# MKL28T7_CORE1 register map
Vendor: Freescale Semiconductor, Inc.; Series: Kinetis_L; File version: 1.6
CPU: CM0PLUS r0p0, little endian, no MPU, no FPU, VTOR, 2 interrupt priority bits
Registers are 32-bit, read-write, reset 0x0 unless marked. A register's access mark holds for its fields unless they carry their own. Offsets are from the block's base; [hi:lo] are bit positions; {n}, {i} and the like mark numbered series.

## VREF — Voltage Reference
Base 0x40072000; register names take the prefix VREF_
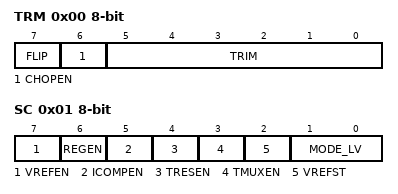
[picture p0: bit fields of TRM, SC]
0x00 TRM 8-bit (reset mask 0xC0) — VREF Trim Register
  [7] FLIP — Reverses the amplifier polarity
  [6] CHOPEN — Chop oscillator enable. When set, the internal chopping operation is enabled and the internal analog offset will be minimized.
    0=Chop oscillator is disabled; 1=Chop oscillator is enabled
  [5:0] TRIM — Trim bits
    0=Min; 63=Max
0x01 SC 8-bit — VREF Status and Control Register
  [7] VREFEN — Internal Voltage Reference enable
    0=The module is disabled; 1=The module is enabled
  [6] REGEN — Regulator enable
    0=Internal 1.75 V regulator is disabled; 1=Internal 1.75 V regulator is enabled
  [5] ICOMPEN — Second order curvature compensation enable
    0=Disabled; 1=Enabled
  [4] TRESEN — Test second order curvature compensation enable
    0=Disabled; 1=Enabled
  [3] TMUXEN — Test MUX enable
    0=Disabled; 1=Enabled
  [2] VREFST ro — Internal Voltage Reference stable
    0=The module is disabled or not stable; 1=The module is stable
  [1:0] MODE_LV — Buffer Mode selection
    0=Bandgap on only, for stabilization and startup; 1=High power buffer mode enabled; 2=Low-power buffer mode enabled
0x05 TRM4 8-bit — VREF Trim Register 4
  [7] VREF2V1_EN — Internal Voltage Reference (2.1V) Enable
    0=VREF 2.1V is disabled; 1=VREF 2.1V is enabled

## SIM — System Integration Module
Base 0x40074000; register names take the prefix SIM_
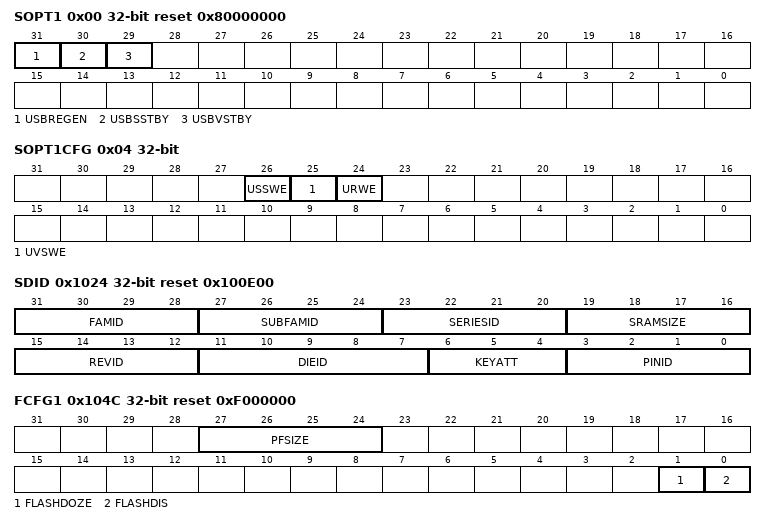
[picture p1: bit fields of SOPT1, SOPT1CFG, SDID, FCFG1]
0x00 SOPT1 reset 0x80000000 — System Options Register 1
  [31] USBREGEN — USB voltage regulator enable
    0=USB voltage regulator is disabled; 1=USB voltage regulator is enabled
  [30] USBSSTBY — USB voltage regulator in standby mode during Stop, VLPS, LLS and VLLS modes.
    0=USB voltage regulator not in standby during Stop, VLPS, LLS and VLLS modes; 1=USB voltage regulator in standby during Stop, VLPS, LLS and VLLS modes
  [29] USBVSTBY — USB voltage regulator in standby mode during VLPR and VLPW modes
    0=USB voltage regulator not in standby during VLPR and VLPW modes; 1=USB voltage regulator in standby during VLPR and VLPW modes
0x04 SOPT1CFG — SOPT1 Configuration Register
  [26] USSWE — USB voltage regulator stop standby write enable
    0=SOPT1 USBSSTB cannot be written; 1=SOPT1 USBSSTB can be written
  [25] UVSWE — USB voltage regulator VLP standby write enable
    0=SOPT1 USBVSTB cannot be written; 1=SOPT1 USBVSTB can be written
  [24] URWE — USB voltage regulator enable write enable
    0=SOPT1 USBREGEN cannot be written; 1=SOPT1 USBREGEN can be written
0x1024 SDID ro reset 0x100E00 — System Device Identification Register
  [31:28] FAMID — Kinetis family ID
    2=KL2x Family (USB)
  [27:24] SUBFAMID — Kinetis Sub-Family ID
    {v}=KLx{v} Subfamily (v=2..9)
  [23:20] SERIESID — Kinetis Series ID
    1=KL family
  [19:16] SRAMSIZE — System SRAM Size
    8=96 KB; 9=128 KB
  [15:12] REVID — Device Revision Number
  [11:7] DIEID — Device Die Number
  [6:4] KEYATT — Core configuration of the device.
    0=Cortex CM0+ Core; 1=Cortex CM0+ Core with additional Core (Core0 and Core1)
  [3:0] PINID — Pin count identification
    0=16-pin; 1=24-pin; 2=32-pin; 3=36-pin; 4=48-pin; 5=64-pin; 6=80-pin; 8=100-pin; 9=121-pin; 11=Custom pin-out(WLCSP)
0x104C FCFG1 reset 0xF000000 — Flash Configuration Register 1
  [27:24] PFSIZE ro — Program Flash Size
    5=64 KB of program flash memory, 2 KB protection region; 7=128 KB of program flash memory, 4 KB protection region; 9=256 KB of program flash memory, 8 KB protection region; 11=512 KB of program flash memory, 16 KB protection region
  [1] FLASHDOZE
    0=Flash remains enabled during Doze mode; 1=Flash is disabled for the duration of Doze mode
  [0] FLASHDIS — Flash Disable
    0=Flash is enabled; 1=Flash is disabled
0x1050 FCFG2 ro reset 0x7FA00000 — Flash Configuration Register 2
  [30:24] MAXADDR0 — Max Address lock
0x1058 UIDMH ro — Unique Identification Register Mid-High
  [15:0] UID — Unique Identification
0x105C UIDML ro — Unique Identification Register Mid Low
  [31:0] UID — Unique Identification
0x1060 UIDL ro — Unique Identification Register Low
  [31:0] UID — Unique Identification
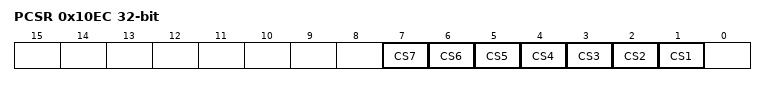
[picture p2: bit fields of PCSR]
0x10EC PCSR ro — Peripheral Clock Status Register
  [all] fields
    0=Clock not ready; 1=Clock ready
  [n] CS{n} (n=1..7) — Clock Source {n}
